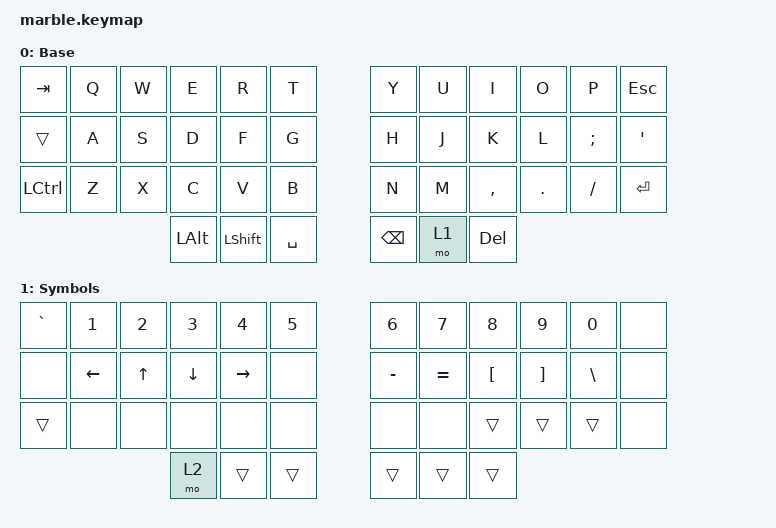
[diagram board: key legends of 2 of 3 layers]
#include <behaviors.dtsi>
#include <dt-bindings/zmk/keys.h>
#include <dt-bindings/zmk/bt.h>

/ {
    keymap {
        compatible = "zmk,keymap";

        default_layer {
            display-name = "Base";
            bindings = <
                &kp TAB      &kp Q        &kp W        &kp E    &kp R      &kp T                 &kp Y     &kp U     &kp I     &kp O    &kp P     &kp ESC
                &trans       &kp A        &kp S        &kp D    &kp F      &kp G                 &kp H     &kp J     &kp K     &kp L    &kp SEMI  &kp SQT
                &kp LCTRL    &kp Z        &kp X        &kp C    &kp V      &kp B                 &kp N     &kp M     &kp COMMA &kp DOT  &kp SLASH &kp ENTER
                                                       &kp LALT &kp LSHIFT &kp SPACE             &kp BSPC  &mo 1     &kp DEL
            >;
        };
        symbols_layer {
            display-name = "Symbols";
            bindings = <
                &kp GRAVE    &kp N1       &kp N2       &kp N3   &kp N4     &kp N5                &kp N6    &kp N7    &kp N8    &kp N9   &kp N0    &none
                &none        &kp LEFT     &kp UP       &kp DOWN &kp RIGHT  &none                 &kp MINUS &kp EQUAL &kp LBKT  &kp RBKT &kp BSLH  &none
                &trans       &none        &none        &none    &none      &none                 &none     &none     &trans    &trans   &trans    &none
                                                       &mo 2    &trans     &trans                &trans    &trans    &trans
            >;
        };
        function_layer {
            display-name = "Function";
            bindings = <
                &kp F1       &kp F2       &kp F3       &kp F4   &kp F5     &kp F6                  &kp F7    &kp F8    &kp F9    &kp F10  &kp F11   &kp F12
                &none        &none        &none        &none    &none      &none                   &none     &none     &none     &none    &none     &none
                &bt BT_SEL 0 &bt BT_SEL 1 &bt BT_SEL 2 &none    &bt BT_CLR &bt BT_CLR_ALL          &none     &none     &none     &kp LGUI
                                                       &trans   &none      &none                   &none     &trans    &none
            >;
        };
    };
};
